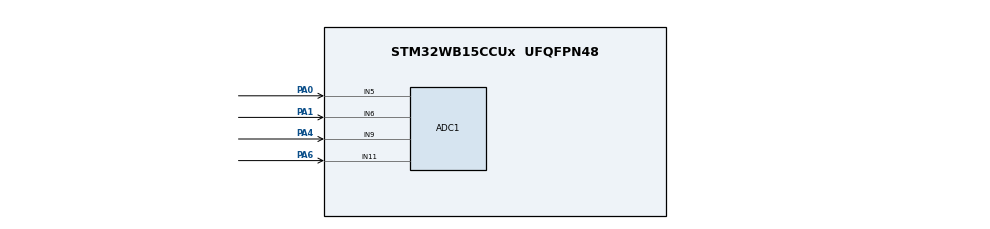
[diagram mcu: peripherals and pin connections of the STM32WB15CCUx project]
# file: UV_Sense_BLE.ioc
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Mcu.Family=STM32WB
Dma.ADC1.0.Instance=DMA1_Channel1
RCC.CortexFreq_Value=32000000
ADC1.Sequencer=FULLY_CONFIGURABLE
SH.ADCx_IN6.0=ADC1_IN6,IN6-Single-Ended
Dma.ADC1.0.SyncRequestNumber=1
Dma.ADC1.0.Polarity=HAL_DMAMUX_REQ_GEN_RISING
ADC1.SamplingTime-6\#ChannelRegularConversion=ADC_SAMPLINGTIME_COMMON_1
ADC1.Rank-8\#ChannelRegularConversion=4
ADC1.SamplingTimeCommon1=ADC_SAMPLETIME_3CYCLES_5
ADC1.Channel-8\#ChannelRegularConversion=ADC_CHANNEL_11
ProjectManager.StackSize=0x400
ADC1.Channel-7\#ChannelRegularConversion=ADC_CHANNEL_9
Dma.ADC1.0.PeriphDataAlignment=DMA_PDATAALIGN_HALFWORD
NVIC.ADC1_IRQn=true\:0\:0\:false\:false\:true\:true\:true
ADC1.Channel-5\#ChannelRegularConversion=ADC_CHANNEL_5
ProjectManager.TargetToolchain=STM32CubeIDE
Dma.ADC1.0.Mode=DMA_CIRCULAR
Dma.ADC1.0.SignalID=NONE
RCC.HCLKFreq_Value=32000000
Dma.ADC1.0.SyncSignalID=NONE
Dma.ADC1.0.Priority=DMA_PRIORITY_LOW
RCC.APB2TimFreq_Value=32000000
Dma.ADC1.0.Direction=DMA_PERIPH_TO_MEMORY
RCC.LSE_VALUE=32768
Dma.ADC1.0.MemDataAlignment=DMA_MDATAALIGN_HALFWORD
PA1.Signal=ADCx_IN6
RCC.AHBFreq_Value=32000000
RCC.HSE_VALUE=32000000
board=custom
RCC.VCOOutputFreq_Value=256000000
Dma.ADC1.0.SyncPolarity=HAL_DMAMUX_SYNC_NO_EVENT
ADC1.Channel-6\#ChannelRegularConversion=ADC_CHANNEL_6
RCC.APB2Freq_Value=32000000
SH.ADCx_IN11.0=ADC1_IN11,IN11-Single-Ended
Dma.ADC1.0.PeriphInc=DMA_PINC_DISABLE
ADC1.NbrOfConversion=4
Mcu.Name=STM32WB15CCUx
PA0.Signal=ADCx_IN5
RCC.APB3Freq_Value=16000000
ADC1.SelectedChannel=ADC_CHANNEL_5|ADC_CHANNEL_6|ADC_CHANNEL_9|ADC_CHANNEL_11
PA4.Signal=ADCx_IN9
RCC.SYSCLKFreq_VALUE=32000000
Mcu.Package=UFQFPN48
PA6.Signal=ADCx_IN11
ADC1.master=1
Dma.ADC1.0.RequestNumber=1
Dma.ADC1.0.SyncEnable=DISABLE
Dma.ADC1.0.MemInc=DMA_MINC_ENABLE
ProjectManager.HeapSize=0x200
SH.ADCx_IN9.0=ADC1_IN9,IN9-Single-Ended
ADC1.SamplingTime-5\#ChannelRegularConversion=ADC_SAMPLINGTIME_COMMON_1
RCC.HSI_VALUE=16000000
SH.ADCx_IN5.0=ADC1_IN5,IN5-Single-Ended
ADC1.Rank-7\#ChannelRegularConversion=3
NVIC.PriorityGroup=NVIC_PRIORITYGROUP_4
ADC1.NbrOfConversionFlag=1
ADC1.EnableRegularConversion=ENABLE
RCC.APB1TimFreq_Value=32000000
ADC1.SamplingTime-7\#ChannelRegularConversion=ADC_SAMPLINGTIME_COMMON_1
NVIC.DMA1_Channel1_IRQn=true\:0\:0\:false\:false\:true\:false\:true
ADC1.Rank-6\#ChannelRegularConversion=2
Dma.Request0=ADC1
RCC.APB1Freq_Value=32000000
ADC1.SamplingTime-8\#ChannelRegularConversion=ADC_SAMPLINGTIME_COMMON_1
RCC.RFWKPClockSelection=RCC_RFWKPCLKSOURCE_HSE_DIV1024
ADC1.ClockPrescaler=ADC_CLOCK_ASYNC_DIV128
ADC1.EOCSelection=ADC_EOC_SINGLE_CONV
ADC1.Rank-5\#ChannelRegularConversion=1
RCC.MSIClockRange=RCC_MSIRANGE_10
Dma.ADC1.0.EventEnable=DISABLE

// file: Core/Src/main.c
/* USER CODE BEGIN Header */
/**
  ******************************************************************************
  * @file           : main.c
  * @brief          : Main program body
  ******************************************************************************
  * @attention
  *
  * <h2><center>&copy; Copyright (c) 2021 STMicroelectronics.
  * All rights reserved.</center></h2>
  *
  * This software component is licensed by ST under BSD 3-Clause license,
  * the "License"; You may not use this file except in compliance with the
  * License. You may obtain a copy of the License at:
  *                        opensource.org/licenses/BSD-3-Clause
  *
  ******************************************************************************
  */
/* USER CODE END Header */
#include "main.h"

/* USER CODE BEGIN Includes */
//#include "uv_sense.h"
/* USER CODE END Includes */

/* USER CODE BEGIN PD */
#define NUM_OF_SENSORS 4
/* USER CODE END PD */

ADC_HandleTypeDef hadc1;
DMA_HandleTypeDef hdma_adc1;

/* USER CODE BEGIN PV */
uint16_t results[NUM_OF_SENSORS];

/* USER CODE END PV */

void SystemClock_Config(void);
static void MX_GPIO_Init(void);
static void MX_DMA_Init(void);
static void MX_ADC1_Init(void);

int main(void)
{

  /* MCU Configuration--------------------------------------------------------*/

  /* Reset of all peripherals, Initializes the Flash interface and the Systick. */
  HAL_Init();

  /* Configure the system clock */
  SystemClock_Config();

  /* Initialize all configured peripherals */
  MX_GPIO_Init();
  MX_DMA_Init();
  MX_ADC1_Init();

  /* Infinite loop */
  /* USER CODE BEGIN WHILE */
  while (1)
  {
	  HAL_ADC_Start_DMA(&hadc1, (uint32_t*)results, NUM_OF_SENSORS);
    /* USER CODE END WHILE */

  }
}

void SystemClock_Config(void)
{
  RCC_OscInitTypeDef RCC_OscInitStruct = {0};
  RCC_ClkInitTypeDef RCC_ClkInitStruct = {0};
  RCC_PeriphCLKInitTypeDef PeriphClkInitStruct = {0};

  /** Initializes the RCC Oscillators according to the specified parameters
  * in the RCC_OscInitTypeDef structure.
  */
  RCC_OscInitStruct.OscillatorType = RCC_OSCILLATORTYPE_HSI|RCC_OSCILLATORTYPE_MSI;
  RCC_OscInitStruct.HSIState = RCC_HSI_ON;
  RCC_OscInitStruct.MSIState = RCC_MSI_ON;
  RCC_OscInitStruct.HSICalibrationValue = RCC_HSICALIBRATION_DEFAULT;
  RCC_OscInitStruct.MSICalibrationValue = RCC_MSICALIBRATION_DEFAULT;
  RCC_OscInitStruct.MSIClockRange = RCC_MSIRANGE_10;
  RCC_OscInitStruct.PLL.PLLState = RCC_PLL_NONE;
  if (HAL_RCC_OscConfig(&RCC_OscInitStruct) != HAL_OK)
  {
    Error_Handler();
  }
  /** Configure the SYSCLKSource, HCLK, PCLK1 and PCLK2 clocks dividers
  */
  RCC_ClkInitStruct.ClockType = RCC_CLOCKTYPE_HCLK4|RCC_CLOCKTYPE_HCLK2
                              |RCC_CLOCKTYPE_HCLK|RCC_CLOCKTYPE_SYSCLK
                              |RCC_CLOCKTYPE_PCLK1|RCC_CLOCKTYPE_PCLK2;
  RCC_ClkInitStruct.SYSCLKSource = RCC_SYSCLKSOURCE_MSI;
  RCC_ClkInitStruct.AHBCLKDivider = RCC_SYSCLK_DIV1;
  RCC_ClkInitStruct.APB1CLKDivider = RCC_HCLK_DIV1;
  RCC_ClkInitStruct.APB2CLKDivider = RCC_HCLK_DIV1;
  RCC_ClkInitStruct.AHBCLK2Divider = RCC_SYSCLK_DIV1;
  RCC_ClkInitStruct.AHBCLK4Divider = RCC_SYSCLK_DIV1;

  if (HAL_RCC_ClockConfig(&RCC_ClkInitStruct, FLASH_LATENCY_1) != HAL_OK)
  {
    Error_Handler();
  }
  /** Initializes the peripherals clocks
  */
  PeriphClkInitStruct.PeriphClockSelection = RCC_PERIPHCLK_SMPS|RCC_PERIPHCLK_ADC;
  PeriphClkInitStruct.AdcClockSelection = RCC_ADCCLKSOURCE_HSI;
  PeriphClkInitStruct.SmpsClockSelection = RCC_SMPSCLKSOURCE_HSI;
  PeriphClkInitStruct.SmpsDivSelection = RCC_SMPSCLKDIV_RANGE1;
  if (HAL_RCCEx_PeriphCLKConfig(&PeriphClkInitStruct) != HAL_OK)
  {
    Error_Handler();
  }
}

static void MX_ADC1_Init(void)
{

  ADC_ChannelConfTypeDef sConfig = {0};

  /** Common config
  */
  hadc1.Instance = ADC1;
  hadc1.Init.ClockPrescaler = ADC_CLOCK_ASYNC_DIV128;
  hadc1.Init.Resolution = ADC_RESOLUTION_12B;
  hadc1.Init.DataAlign = ADC_DATAALIGN_RIGHT;
  hadc1.Init.ScanConvMode = ADC_SCAN_ENABLE;
  hadc1.Init.EOCSelection = ADC_EOC_SINGLE_CONV;
  hadc1.Init.SamplingTimeCommon1 = ADC_SAMPLETIME_3CYCLES_5;
  hadc1.Init.SamplingTimeCommon2 = ADC_SAMPLETIME_1CYCLE_5;
  hadc1.Init.LowPowerAutoWait = DISABLE;
  hadc1.Init.ContinuousConvMode = DISABLE;
  hadc1.Init.NbrOfConversion = 4;
  hadc1.Init.DiscontinuousConvMode = DISABLE;
  hadc1.Init.ExternalTrigConv = ADC_SOFTWARE_START;
  hadc1.Init.ExternalTrigConvEdge = ADC_EXTERNALTRIGCONVEDGE_NONE;
  hadc1.Init.DMAContinuousRequests = DISABLE;
  hadc1.Init.Overrun = ADC_OVR_DATA_PRESERVED;
  if (HAL_ADC_Init(&hadc1) != HAL_OK)
  {
    Error_Handler();
  }
  /** Configure Regular Channel
  */
  sConfig.Channel = ADC_CHANNEL_5;
  sConfig.Rank = ADC_REGULAR_RANK_1;
  sConfig.SamplingTime = ADC_SAMPLINGTIME_COMMON_1;
  if (HAL_ADC_ConfigChannel(&hadc1, &sConfig) != HAL_OK)
  {
    Error_Handler();
  }
  /** Configure Regular Channel
  */
  sConfig.Channel = ADC_CHANNEL_6;
  sConfig.Rank = ADC_REGULAR_RANK_2;
  if (HAL_ADC_ConfigChannel(&hadc1, &sConfig) != HAL_OK)
  {
    Error_Handler();
  }
  /** Configure Regular Channel
  */
  sConfig.Channel = ADC_CHANNEL_9;
  sConfig.Rank = ADC_REGULAR_RANK_3;
  if (HAL_ADC_ConfigChannel(&hadc1, &sConfig) != HAL_OK)
  {
    Error_Handler();
  }
  /** Configure Regular Channel
  */
  sConfig.Channel = ADC_CHANNEL_11;
  sConfig.Rank = ADC_REGULAR_RANK_4;
  if (HAL_ADC_ConfigChannel(&hadc1, &sConfig) != HAL_OK)
  {
    Error_Handler();
  }

}

static void MX_DMA_Init(void)
{

  /* DMA controller clock enable */
  __HAL_RCC_DMAMUX1_CLK_ENABLE();
  __HAL_RCC_DMA1_CLK_ENABLE();

  /* DMA interrupt init */
  /* DMA1_Channel1_IRQn interrupt configuration */
  HAL_NVIC_SetPriority(DMA1_Channel1_IRQn, 0, 0);
  HAL_NVIC_EnableIRQ(DMA1_Channel1_IRQn);

}

static void MX_GPIO_Init(void)
{

  /* GPIO Ports Clock Enable */
  __HAL_RCC_GPIOA_CLK_ENABLE();

}

/* USER CODE BEGIN 4 */
void DMATransferComplete() {
	while(1) {
		__NOP();
	}
}
/* USER CODE END 4 */

void Error_Handler(void)
{
  __disable_irq();
  while (1)
  {
  }
}

/************************ (C) COPYRIGHT STMicroelectronics *****END OF FILE****/
